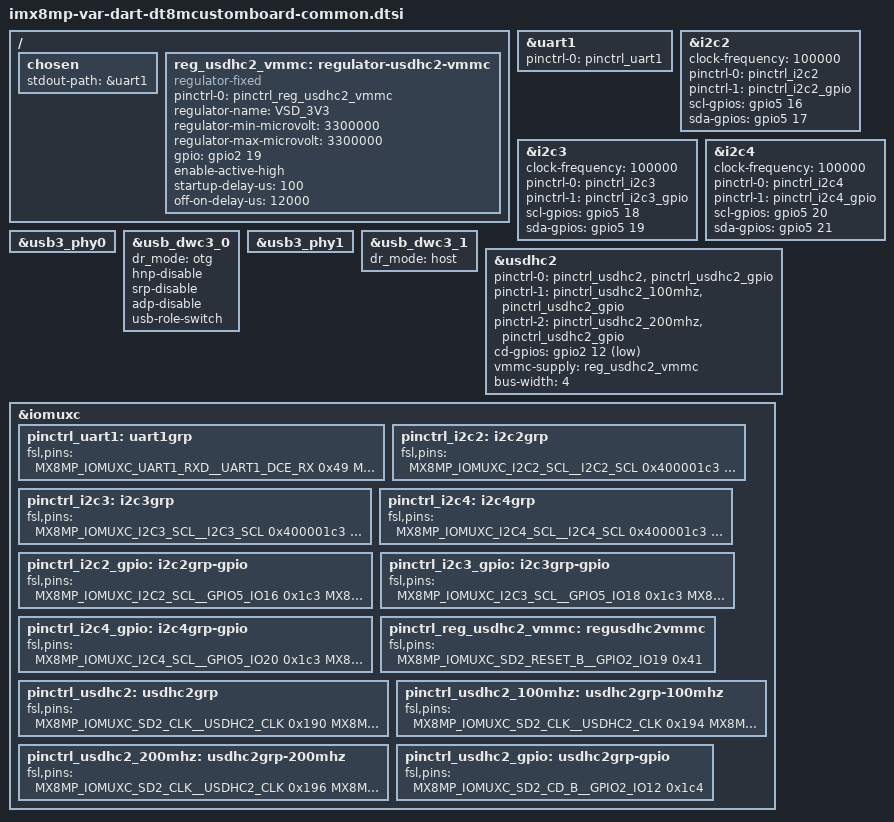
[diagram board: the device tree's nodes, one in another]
// SPDX-License-Identifier: (GPL-2.0+ OR MIT)
/*
 * Copyright 2019 NXP
 * Copyright 2020-2021 Variscite Ltd.
 */

/ {
	chosen {
		stdout-path = &uart1;
	};

	reg_usdhc2_vmmc: regulator-usdhc2-vmmc {
		compatible = "regulator-fixed";
		pinctrl-names = "default";
		pinctrl-0 = <&pinctrl_reg_usdhc2_vmmc>;
		regulator-name = "VSD_3V3";
		regulator-min-microvolt = <3300000>;
		regulator-max-microvolt = <3300000>;
		gpio = <&gpio2 19 GPIO_ACTIVE_HIGH>;
		enable-active-high;
		startup-delay-us = <100>;
		off-on-delay-us = <12000>;
	};
};

&uart1 {
	pinctrl-names = "default";
	pinctrl-0 = <&pinctrl_uart1>;
	status = "okay";
};

&i2c2 {
	clock-frequency = <100000>;
	pinctrl-names = "default", "gpio";
	pinctrl-0 = <&pinctrl_i2c2>;
	pinctrl-1 = <&pinctrl_i2c2_gpio>;
	scl-gpios = <&gpio5 16 GPIO_ACTIVE_HIGH>;
	sda-gpios = <&gpio5 17 GPIO_ACTIVE_HIGH>;
	status = "okay";
};

&i2c3 {
	clock-frequency = <100000>;
	pinctrl-names = "default", "gpio";
	pinctrl-0 = <&pinctrl_i2c3>;
	pinctrl-1 = <&pinctrl_i2c3_gpio>;
	scl-gpios = <&gpio5 18 GPIO_ACTIVE_HIGH>;
	sda-gpios = <&gpio5 19 GPIO_ACTIVE_HIGH>;
	status = "okay";
};

&i2c4 {
	clock-frequency = <100000>;
	pinctrl-names = "default", "gpio";
	pinctrl-0 = <&pinctrl_i2c4>;
	pinctrl-1 = <&pinctrl_i2c4_gpio>;
	scl-gpios = <&gpio5 20 GPIO_ACTIVE_HIGH>;
	sda-gpios = <&gpio5 21 GPIO_ACTIVE_HIGH>;
	status = "okay";
};

&usb3_phy0 {
	status = "okay";
};

&usb_dwc3_0 {
	dr_mode = "otg";
	hnp-disable;
	srp-disable;
	adp-disable;
	usb-role-switch;
	status = "okay";
};

&usb3_phy1 {
	status = "okay";
};

&usb_dwc3_1 {
	dr_mode = "host";
	status = "okay";
};

&usdhc2 {
	pinctrl-names = "default", "state_100mhz", "state_200mhz";
	pinctrl-0 = <&pinctrl_usdhc2>, <&pinctrl_usdhc2_gpio>;
	pinctrl-1 = <&pinctrl_usdhc2_100mhz>, <&pinctrl_usdhc2_gpio>;
	pinctrl-2 = <&pinctrl_usdhc2_200mhz>, <&pinctrl_usdhc2_gpio>;
	cd-gpios = <&gpio2 12 GPIO_ACTIVE_LOW>;
	vmmc-supply = <&reg_usdhc2_vmmc>;
	bus-width = <4>;
	status = "okay";
};

&iomuxc {

	pinctrl_uart1: uart1grp {
		fsl,pins = <
			MX8MP_IOMUXC_UART1_RXD__UART1_DCE_RX				0x49
			MX8MP_IOMUXC_UART1_TXD__UART1_DCE_TX				0x49
		>;
	};

	pinctrl_i2c2: i2c2grp {
		fsl,pins = <
			MX8MP_IOMUXC_I2C2_SCL__I2C2_SCL					0x400001c3
			MX8MP_IOMUXC_I2C2_SDA__I2C2_SDA					0x400001c3
		>;
	};

	pinctrl_i2c3: i2c3grp {
		fsl,pins = <
			MX8MP_IOMUXC_I2C3_SCL__I2C3_SCL					0x400001c3
			MX8MP_IOMUXC_I2C3_SDA__I2C3_SDA					0x400001c3
		>;
	};

	pinctrl_i2c4: i2c4grp {
		fsl,pins = <
			MX8MP_IOMUXC_I2C4_SCL__I2C4_SCL					0x400001c3
			MX8MP_IOMUXC_I2C4_SDA__I2C4_SDA					0x400001c3
		>;
	};

	pinctrl_i2c2_gpio: i2c2grp-gpio {
		fsl,pins = <
			MX8MP_IOMUXC_I2C2_SCL__GPIO5_IO16				0x1c3
			MX8MP_IOMUXC_I2C2_SDA__GPIO5_IO17				0x1c3
		>;
	};

	pinctrl_i2c3_gpio: i2c3grp-gpio {
		fsl,pins = <
			MX8MP_IOMUXC_I2C3_SCL__GPIO5_IO18				0x1c3
			MX8MP_IOMUXC_I2C3_SDA__GPIO5_IO19				0x1c3
		>;
	};

	pinctrl_i2c4_gpio: i2c4grp-gpio {
		fsl,pins = <
			MX8MP_IOMUXC_I2C4_SCL__GPIO5_IO20				0x1c3
			MX8MP_IOMUXC_I2C4_SDA__GPIO5_IO21				0x1c3
		>;
	};

	pinctrl_reg_usdhc2_vmmc: regusdhc2vmmc {
		fsl,pins = <
			MX8MP_IOMUXC_SD2_RESET_B__GPIO2_IO19				0x41
		>;
	};

	pinctrl_usdhc2: usdhc2grp {
		fsl,pins = <
			MX8MP_IOMUXC_SD2_CLK__USDHC2_CLK				0x190
			MX8MP_IOMUXC_SD2_CMD__USDHC2_CMD				0x1d0
			MX8MP_IOMUXC_SD2_DATA0__USDHC2_DATA0				0x1d0
			MX8MP_IOMUXC_SD2_DATA1__USDHC2_DATA1				0x1d0
			MX8MP_IOMUXC_SD2_DATA2__USDHC2_DATA2				0x1d0
			MX8MP_IOMUXC_SD2_DATA3__USDHC2_DATA3				0x1d0
			MX8MP_IOMUXC_GPIO1_IO04__USDHC2_VSELECT				0xc1
		>;
	};

	pinctrl_usdhc2_100mhz: usdhc2grp-100mhz {
		fsl,pins = <
			MX8MP_IOMUXC_SD2_CLK__USDHC2_CLK				0x194
			MX8MP_IOMUXC_SD2_CMD__USDHC2_CMD				0x1d4
			MX8MP_IOMUXC_SD2_DATA0__USDHC2_DATA0				0x1d4
			MX8MP_IOMUXC_SD2_DATA1__USDHC2_DATA1				0x1d4
			MX8MP_IOMUXC_SD2_DATA2__USDHC2_DATA2				0x1d4
			MX8MP_IOMUXC_SD2_DATA3__USDHC2_DATA3				0x1d4
			MX8MP_IOMUXC_GPIO1_IO04__USDHC2_VSELECT 			0xc1
		>;
	};

	pinctrl_usdhc2_200mhz: usdhc2grp-200mhz {
		fsl,pins = <
			MX8MP_IOMUXC_SD2_CLK__USDHC2_CLK				0x196
			MX8MP_IOMUXC_SD2_CMD__USDHC2_CMD				0x1d6
			MX8MP_IOMUXC_SD2_DATA0__USDHC2_DATA0				0x1d6
			MX8MP_IOMUXC_SD2_DATA1__USDHC2_DATA1				0x1d6
			MX8MP_IOMUXC_SD2_DATA2__USDHC2_DATA2				0x1d6
			MX8MP_IOMUXC_SD2_DATA3__USDHC2_DATA3				0x1d6
			MX8MP_IOMUXC_GPIO1_IO04__USDHC2_VSELECT 			0xc1
		>;
	};

	pinctrl_usdhc2_gpio: usdhc2grp-gpio {
		fsl,pins = <
			MX8MP_IOMUXC_SD2_CD_B__GPIO2_IO12				0x1c4
		>;
	};
};
